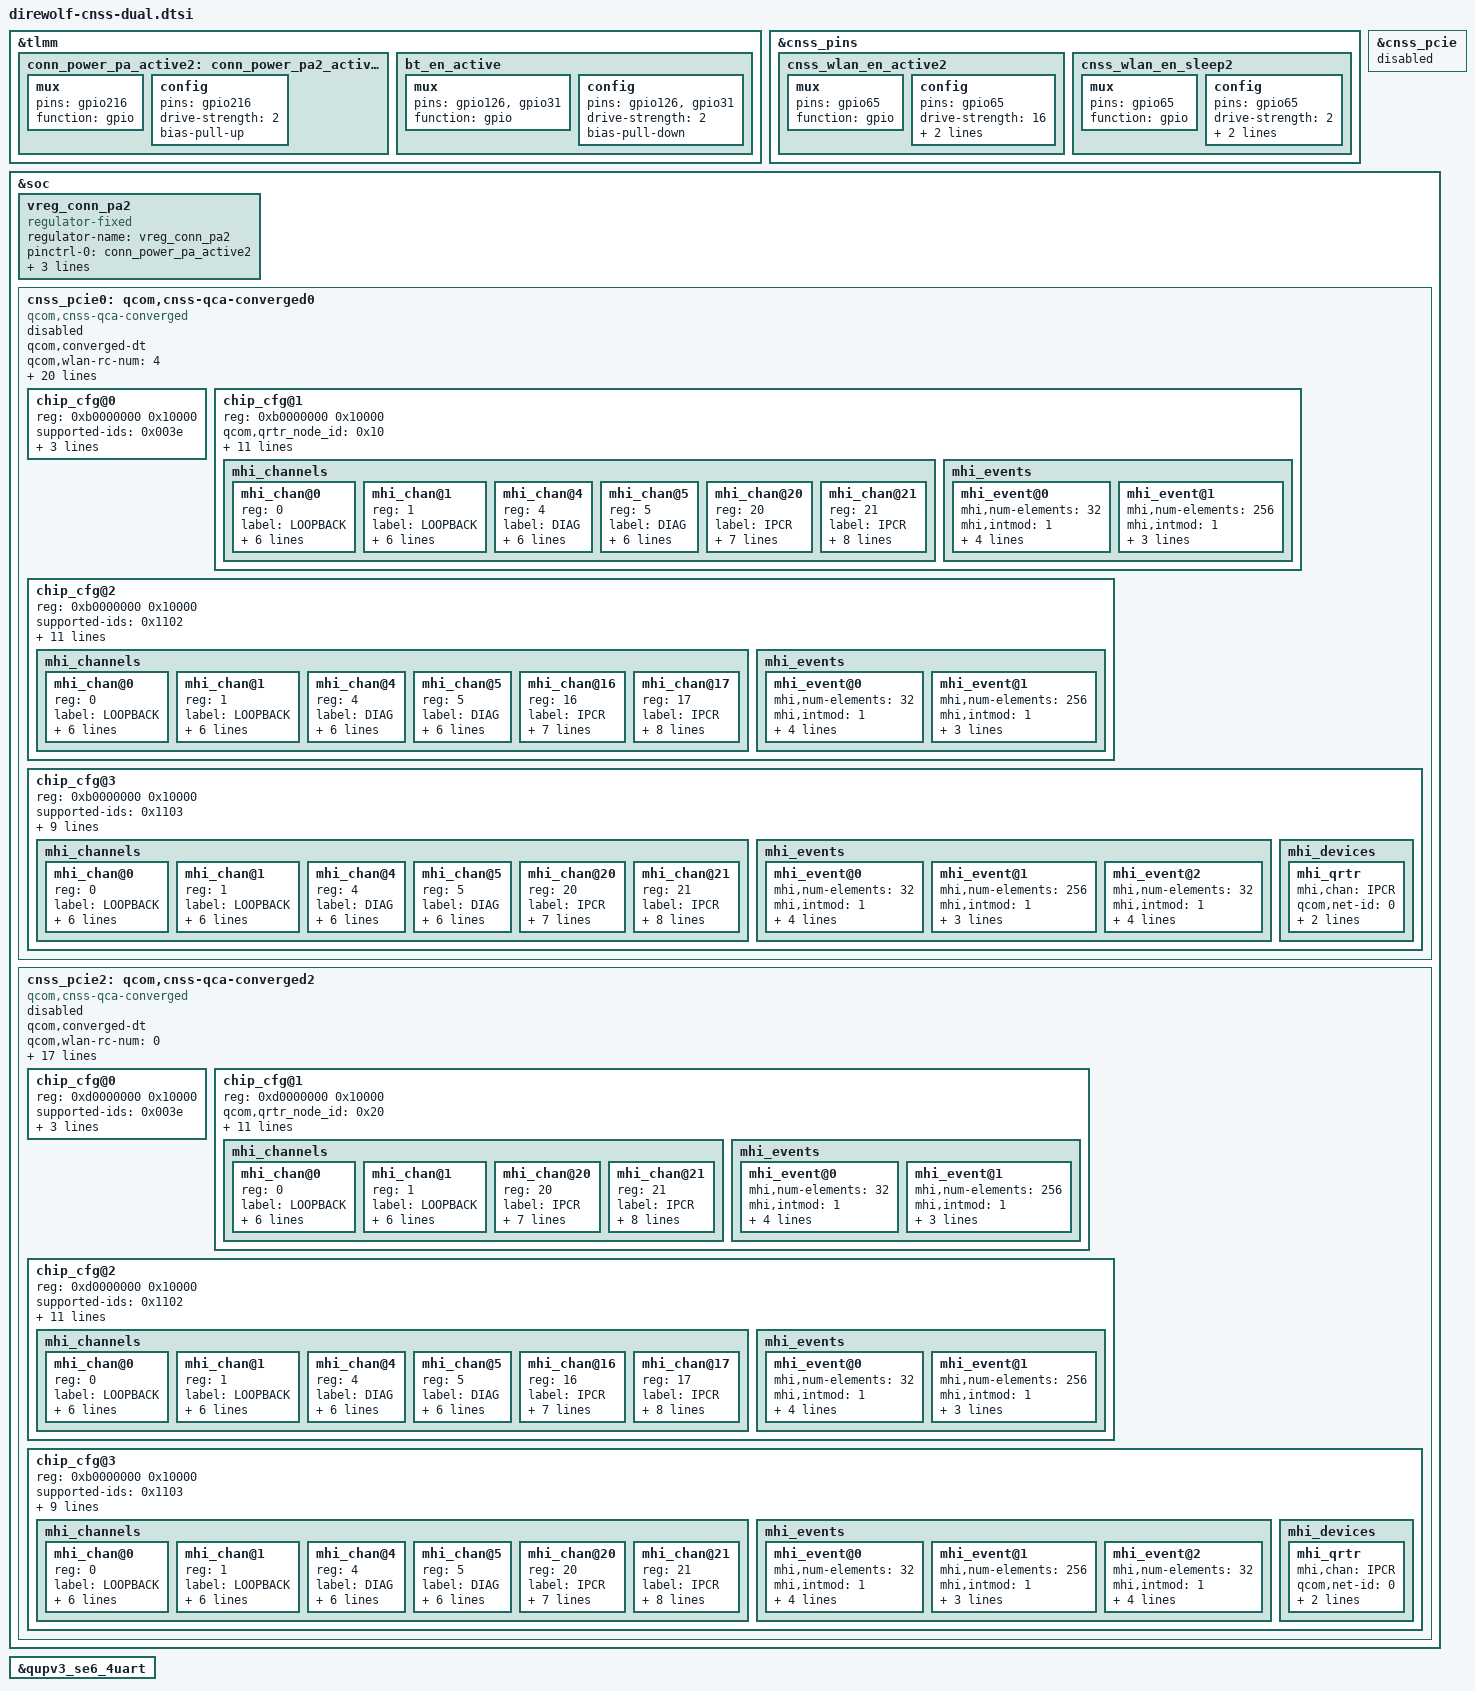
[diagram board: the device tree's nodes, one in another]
&tlmm {
	conn_power_pa_active2: conn_power_pa2_active2 {
		mux {
			pins = "gpio216";
			function = "gpio";
		};

		config {
			pins = "gpio216";
			drive-strength = <2>;
			bias-pull-up;
		};
	};
};

&cnss_pins {
	cnss_wlan_en_active2: cnss_wlan_en_active2 {
		mux {
			pins = "gpio65";
			function = "gpio";
		};

		config {
			pins = "gpio65";
			drive-strength = <16>;
			output-high;
			bias-pull-up;
		};
	};

	cnss_wlan_en_sleep2: cnss_wlan_en_sleep2 {
		mux {
			pins = "gpio65";
			function = "gpio";
		};

		config {
			pins = "gpio65";
			drive-strength = <2>;
			output-low;
			bias-pull-down;
		};
	};
};

&cnss_pcie {
	status = "disabled";
};

&soc {
	/* PWR_CTR1_VDD_PA supply for wlan2 */
	vreg_conn_pa2: vreg_conn_pa2 {
		compatible = "regulator-fixed";
		regulator-name = "vreg_conn_pa2";
		pinctrl-names = "default";
		pinctrl-0 = <&conn_power_pa_active2>;
		startup-delay-us = <4000>;
		enable-active-high;
		gpio = <&tlmm 216 0>;
	};

	/* Support Dual Hastings case */
	cnss_pcie0: qcom,cnss-qca-converged0 {
		compatible = "qcom,cnss-qca-converged";

		qcom,converged-dt;
		qcom,wlan-rc-num = <4>;
		qcom,pld_bus_ops_name = "pld_pcie_cnss2";
		qcom,bus-type=<0>;
		qcom,notify-modem-status;

		#address-cells=<1>;
		#size-cells=<1>;
		ranges = <0xb0000000 0xb0000000 0x10000>;

		vdd-wlan-ctrl1-supply = <&vreg_conn_pa>;
		vdd-wlan-ctrl2-supply = <&vreg_conn_1p8>;
		vdd-wlan-supply = <&vreg_wlan>;
		vdd-wlan-vl-supply = <&pm8540_e0_s4>;
		vdd-wlan-vm-supply = <&pm8540_g0_l6>;
		vdd-wlan-vh-supply = <&pm8540_a0_l15>;

		wlan_vregs = "vdd-wlan-ctrl1", "vdd-wlan-ctrl2", "vdd-wlan-vl",
				"vdd-wlan-vm", "vdd-wlan-vh";
		qcom,vdd-wlan-ctrl1-config = <0 0 0 0 0>;
		qcom,vdd-wlan-ctrl2-config = <0 0 0 0 0>;
		/* no vote-off as sw_ctrl is not supported */
		qcom,vdd-wlan-vl-config = <1055000 1055000 0 0 0>;
		/* No vol setting for bypass LDOs */
		qcom,vdd-wlan-vm-config = <0 0 0 0 0>;
		qcom,vdd-wlan-vh-config = <0 0 0 0 0>;
		wlan-en-gpio = <&tlmm 125 0>;
		qcom,bt-en-gpio = <&tlmm 126 0>;
		pinctrl-names = "wlan_en_active", "wlan_en_sleep";
		pinctrl-0 = <&cnss_wlan_en_active>;
		pinctrl-1 = <&cnss_wlan_en_sleep>;

		status = "disabled";

		chip_cfg@0 {
			reg = <0xb0000000 0x10000>;
			reg-names = "smmu_iova_ipa";

			supported-ids = <0x003e>;
			wlan_vregs = "vdd-wlan";
			qcom,vdd-wlan-config = <0 0 0 10 1>;

			qcom,wlan-ramdump-dynamic = <0x200000>;
		};

		chip_cfg@1 {
			reg = <0xb0000000 0x10000>;
			reg-names = "smmu_iova_ipa";
			qcom,qrtr_node_id = <0x10>;
			supported-ids = <0x1101>;
			wlan_vregs = "vdd-wlan-vl", "vdd-wlan-vm",
				   "vdd-wlan-vh";
			qcom,vdd-wlan-vl-config = <1055000 1055000 0 0 0>;
			qcom,vdd-wlan-vm-config = <0 0 0 0 0>;
			qcom,vdd-wlan-vh-config = <0 0 0 0 0>;

			qcom,wlan-ramdump-dynamic = <0x400000>;
			mhi,max-channels = <30>;
			mhi,timeout = <10000>;
			mhi,buffer-len = <0x8000>;
			mhi,m2-no-db-access;

			mhi_channels {
				#address-cells = <1>;
				#size-cells = <0>;
				mhi_chan@0 {
					reg = <0>;
					label = "LOOPBACK";
					mhi,num-elements = <32>;
					mhi,event-ring = <1>;
					mhi,chan-dir = <1>;
					mhi,data-type = <0>;
					mhi,doorbell-mode = <2>;
					mhi,ee = <0x14>;
				};

				mhi_chan@1 {
					reg = <1>;
					label = "LOOPBACK";
					mhi,num-elements = <32>;
					mhi,event-ring = <1>;
					mhi,chan-dir = <2>;
					mhi,data-type = <0>;
					mhi,doorbell-mode = <2>;
					mhi,ee = <0x14>;
				};

				mhi_chan@4 {
					reg = <4>;
					label = "DIAG";
					mhi,num-elements = <32>;
					mhi,event-ring = <1>;
					mhi,chan-dir = <1>;
					mhi,data-type = <0>;
					mhi,doorbell-mode = <2>;
					mhi,ee = <0x14>;
				};

				mhi_chan@5 {
					reg = <5>;
					label = "DIAG";
					mhi,num-elements = <32>;
					mhi,event-ring = <1>;
					mhi,chan-dir = <2>;
					mhi,data-type = <0>;
					mhi,doorbell-mode = <2>;
					mhi,ee = <0x14>;
				};

				mhi_chan@20 {
					reg = <20>;
					label = "IPCR";
					mhi,num-elements = <32>;
					mhi,event-ring = <1>;
					mhi,chan-dir = <1>;
					mhi,data-type = <1>;
					mhi,doorbell-mode = <2>;
					mhi,ee = <0x14>;
					mhi,auto-start;
				};

				mhi_chan@21 {
					reg = <21>;
					label = "IPCR";
					mhi,num-elements = <32>;
					mhi,event-ring = <1>;
					mhi,chan-dir = <2>;
					mhi,data-type = <0>;
					mhi,doorbell-mode = <2>;
					mhi,ee = <0x14>;
					mhi,auto-queue;
					mhi,auto-start;
				};
			};

			mhi_events {
				mhi_event@0 {
					mhi,num-elements = <32>;
					mhi,intmod = <1>;
					mhi,msi = <1>;
					mhi,priority = <1>;
					mhi,brstmode = <2>;
					mhi,data-type = <1>;
				};

				mhi_event@1 {
					mhi,num-elements = <256>;
					mhi,intmod = <1>;
					mhi,msi = <2>;
					mhi,priority = <1>;
					mhi,brstmode = <2>;
				};
			};
		};

		chip_cfg@2 {
			reg = <0xb0000000 0x10000>;
			reg-names = "smmu_iova_ipa";

			supported-ids = <0x1102>;
			wlan_vregs = "vdd-wlan-vl", "vdd-wlan-vm",
				   "vdd-wlan-vh";
			qcom,vdd-wlan-vl-config = <1055000 1055000 0 0 0>;
			qcom,vdd-wlan-vm-config = <0 0 0 0 0>;
			qcom,vdd-wlan-vh-config = <0 0 0 0 0>;

			qcom,wlan-ramdump-dynamic = <0x300000>;
			mhi,max-channels = <30>;
			mhi,timeout = <10000>;
			mhi,ee = <0x3>, <0x4>;
			mhi,ee-names = "SBL", "RDDM";
			mhi,bhie-offset = <0x0324>;

			mhi_channels {
				#address-cells = <1>;
				#size-cells = <0>;
				mhi_chan@0 {
					reg = <0>;
					label = "LOOPBACK";
					mhi,num-elements = <32>;
					mhi,event-ring = <1>;
					mhi,chan-dir = <1>;
					mhi,data-type = <0>;
					mhi,doorbell-mode = <2>;
					mhi,ee = <0x14>;
				};

				mhi_chan@1 {
					reg = <1>;
					label = "LOOPBACK";
					mhi,num-elements = <32>;
					mhi,event-ring = <1>;
					mhi,chan-dir = <2>;
					mhi,data-type = <0>;
					mhi,doorbell-mode = <2>;
					mhi,ee = <0x14>;
				};

				mhi_chan@4 {
					reg = <4>;
					label = "DIAG";
					mhi,num-elements = <32>;
					mhi,event-ring = <1>;
					mhi,chan-dir = <1>;
					mhi,data-type = <0>;
					mhi,doorbell-mode = <2>;
					mhi,ee = <0x14>;
				};

				mhi_chan@5 {
					reg = <5>;
					label = "DIAG";
					mhi,num-elements = <32>;
					mhi,event-ring = <1>;
					mhi,chan-dir = <2>;
					mhi,data-type = <0>;
					mhi,doorbell-mode = <2>;
					mhi,ee = <0x14>;
				};

				mhi_chan@16 {
					reg = <16>;
					label = "IPCR";
					mhi,num-elements = <32>;
					mhi,event-ring = <1>;
					mhi,chan-dir = <1>;
					mhi,data-type = <1>;
					mhi,doorbell-mode = <2>;
					mhi,ee = <0x14>;
					mhi,auto-start;
				};

				mhi_chan@17 {
					reg = <17>;
					label = "IPCR";
					mhi,num-elements = <32>;
					mhi,event-ring = <1>;
					mhi,chan-dir = <2>;
					mhi,data-type = <0>;
					mhi,doorbell-mode = <2>;
					mhi,ee = <0x14>;
					mhi,auto-queue;
					mhi,auto-start;
				};
			};

			mhi_events {
				mhi_event@0 {
					mhi,num-elements = <32>;
					mhi,intmod = <1>;
					mhi,msi = <1>;
					mhi,priority = <1>;
					mhi,brstmode = <2>;
					mhi,data-type = <1>;
				};

				mhi_event@1 {
					mhi,num-elements = <256>;
					mhi,intmod = <1>;
					mhi,msi = <2>;
					mhi,priority = <1>;
					mhi,brstmode = <2>;
				};
			};
		};

		chip_cfg@3 {
			reg = <0xb0000000 0x10000>;
			reg-names = "smmu_iova_ipa";

			supported-ids = <0x1103>;
			wlan_vregs = "vdd-wlan-vl", "vdd-wlan-vm",
				     "vdd-wlan-vh";
			qcom,vdd-wlan-vl-config = <1055000 1055000 0 0 0>;
			qcom,vdd-wlan-vm-config = <0 0 0 0 0>;
			qcom,vdd-wlan-vh-config = <0 0 0 0 0>;

			qcom,wlan-ramdump-dynamic = <0x420000>;
			mhi,max-channels = <30>;
			mhi,timeout = <10000>;
			mhi,m2-no-db-access;

			mhi_channels {
				#address-cells = <1>;
				#size-cells = <0>;
				mhi_chan@0 {
					reg = <0>;
					label = "LOOPBACK";
					mhi,num-elements = <32>;
					mhi,event-ring = <1>;
					mhi,chan-dir = <1>;
					mhi,data-type = <0>;
					mhi,doorbell-mode = <2>;
					mhi,ee = <0x14>;
				};

				mhi_chan@1 {
					reg = <1>;
					label = "LOOPBACK";
					mhi,num-elements = <32>;
					mhi,event-ring = <1>;
					mhi,chan-dir = <2>;
					mhi,data-type = <0>;
					mhi,doorbell-mode = <2>;
					mhi,ee = <0x14>;
				};

				mhi_chan@4 {
					reg = <4>;
					label = "DIAG";
					mhi,num-elements = <32>;
					mhi,event-ring = <1>;
					mhi,chan-dir = <1>;
					mhi,data-type = <0>;
					mhi,doorbell-mode = <2>;
					mhi,ee = <0x14>;
				};

				mhi_chan@5 {
					reg = <5>;
					label = "DIAG";
					mhi,num-elements = <32>;
					mhi,event-ring = <1>;
					mhi,chan-dir = <2>;
					mhi,data-type = <0>;
					mhi,doorbell-mode = <2>;
					mhi,ee = <0x14>;
				};

				mhi_chan@20 {
					reg = <20>;
					label = "IPCR";
					mhi,num-elements = <32>;
					mhi,event-ring = <1>;
					mhi,chan-dir = <1>;
					mhi,data-type = <1>;
					mhi,doorbell-mode = <2>;
					mhi,ee = <0x14>;
					mhi,auto-start;
				};

				mhi_chan@21 {
					reg = <21>;
					label = "IPCR";
					mhi,num-elements = <32>;
					mhi,event-ring = <1>;
					mhi,chan-dir = <2>;
					mhi,data-type = <0>;
					mhi,doorbell-mode = <2>;
					mhi,ee = <0x14>;
					mhi,auto-queue;
					mhi,auto-start;
				};
			};

			mhi_events {
				mhi_event@0 {
					mhi,num-elements = <32>;
					mhi,intmod = <1>;
					mhi,msi = <1>;
					mhi,priority = <1>;
					mhi,brstmode = <2>;
					mhi,data-type = <1>;
				};

				mhi_event@1 {
					mhi,num-elements = <256>;
					mhi,intmod = <1>;
					mhi,msi = <2>;
					mhi,priority = <1>;
					mhi,brstmode = <2>;
				};

				mhi_event@2 {
					mhi,num-elements = <32>;
					mhi,intmod = <1>;
					mhi,msi = <0>;
					mhi,priority = <2>;
					mhi,brstmode = <2>;
					mhi,data-type = <3>;
				};

			};

			mhi_devices {
				mhi_qrtr {
					mhi,chan = "IPCR";
					qcom,net-id = <0>;
					qcom,low-latency;
					mhi,early-notify;
				};
			};
		};
	};

	cnss_pcie2: qcom,cnss-qca-converged2 {
		compatible = "qcom,cnss-qca-converged";

		qcom,converged-dt;
		qcom,wlan-rc-num = <0>;
		qcom,pld_bus_ops_name = "pld_pcie_cnss0";
		qcom,bus-type=<0>;
		qcom,notify-modem-status;

		#address-cells=<1>;
		#size-cells=<1>;
		ranges = <0xd0000000 0xd0000000 0x10000>;

		vdd-wlan-ctrl1-supply = <&vreg_conn_pa2>;
		/*vdd-wlan-ctrl2-supply = <&vreg_conn_1p8>;*/
		vdd-wlan-supply = <&vreg_wlan>;
		vdd-wlan-vl-supply = <&pm8540_e0_s4>;
		vdd-wlan-vm-supply = <&pm8540_g0_l6>;
		vdd-wlan-vh-supply = <&pm8540_a0_l15>;

		wlan_vregs = "vdd-wlan-ctrl1", "vdd-wlan-vl",
				"vdd-wlan-vm", "vdd-wlan-vh";
		qcom,vdd-wlan-ctrl1-config = <0 0 0 0 0>;
		/*qcom,vdd-wlan-ctrl2-config = <0 0 0 0 0>;*/
		/* no vote-off as sw_ctrl is not supported */
		qcom,vdd-wlan-vl-config = <1055000 1055000 0 0 0>;
		/* No vol setting for bypass LDOs */
		qcom,vdd-wlan-vm-config = <0 0 0 0 0>;
		qcom,vdd-wlan-vh-config = <0 0 0 0 0>;
		wlan-en-gpio = <&tlmm 65 0>;
		pinctrl-names = "wlan_en_active", "wlan_en_sleep";
		pinctrl-0 = <&cnss_wlan_en_active2>;
		pinctrl-1 = <&cnss_wlan_en_sleep2>;

		status = "disabled";

		chip_cfg@0 {
			reg = <0xd0000000 0x10000>;
			reg-names = "smmu_iova_ipa";

			supported-ids = <0x003e>;
			wlan_vregs = "vdd-wlan";
			qcom,vdd-wlan-config = <0 0 0 10 1>;

			qcom,wlan-ramdump-dynamic = <0x200000>;
		};

		chip_cfg@1 {
			reg = <0xd0000000 0x10000>;
			reg-names = "smmu_iova_ipa";
			qcom,qrtr_node_id = <0x20>;
			supported-ids = <0x1101>;
			wlan_vregs = "vdd-wlan-vl", "vdd-wlan-vm",
				   "vdd-wlan-vh";
			qcom,vdd-wlan-vl-config = <1055000 1055000 0 0 0>;
			qcom,vdd-wlan-vm-config = <0 0 0 0 0>;
			qcom,vdd-wlan-vh-config = <0 0 0 0 0>;

			qcom,wlan-ramdump-dynamic = <0x400000>;
			mhi,max-channels = <30>;
			mhi,timeout = <10000>;
			mhi,buffer-len = <0x8000>;
			mhi,m2-no-db-access;

			mhi_channels {
				#address-cells = <1>;
				#size-cells = <0>;
				mhi_chan@0 {
					reg = <0>;
					label = "LOOPBACK";
					mhi,num-elements = <32>;
					mhi,event-ring = <1>;
					mhi,chan-dir = <1>;
					mhi,data-type = <0>;
					mhi,doorbell-mode = <2>;
					mhi,ee = <0x14>;
				};

				mhi_chan@1 {
					reg = <1>;
					label = "LOOPBACK";
					mhi,num-elements = <32>;
					mhi,event-ring = <1>;
					mhi,chan-dir = <2>;
					mhi,data-type = <0>;
					mhi,doorbell-mode = <2>;
					mhi,ee = <0x14>;
				};

				mhi_chan@20 {
					reg = <20>;
					label = "IPCR";
					mhi,num-elements = <32>;
					mhi,event-ring = <1>;
					mhi,chan-dir = <1>;
					mhi,data-type = <1>;
					mhi,doorbell-mode = <2>;
					mhi,ee = <0x14>;
					mhi,auto-start;
				};

				mhi_chan@21 {
					reg = <21>;
					label = "IPCR";
					mhi,num-elements = <32>;
					mhi,event-ring = <1>;
					mhi,chan-dir = <2>;
					mhi,data-type = <0>;
					mhi,doorbell-mode = <2>;
					mhi,ee = <0x14>;
					mhi,auto-queue;
					mhi,auto-start;
				};
			};

			mhi_events {
				mhi_event@0 {
					mhi,num-elements = <32>;
					mhi,intmod = <1>;
					mhi,msi = <1>;
					mhi,priority = <1>;
					mhi,brstmode = <2>;
					mhi,data-type = <1>;
				};

				mhi_event@1 {
					mhi,num-elements = <256>;
					mhi,intmod = <1>;
					mhi,msi = <2>;
					mhi,priority = <1>;
					mhi,brstmode = <2>;
				};
			};
		};

		chip_cfg@2 {
			reg = <0xd0000000 0x10000>;
			reg-names = "smmu_iova_ipa";

			supported-ids = <0x1102>;
			wlan_vregs = "vdd-wlan-vl", "vdd-wlan-vm",
				   "vdd-wlan-vh";
			qcom,vdd-wlan-vl-config = <1055000 1055000 0 0 0>;
			qcom,vdd-wlan-vm-config = <0 0 0 0 0>;
			qcom,vdd-wlan-vh-config = <0 0 0 0 0>;

			qcom,wlan-ramdump-dynamic = <0x300000>;
			mhi,max-channels = <30>;
			mhi,timeout = <10000>;
			mhi,ee = <0x3>, <0x4>;
			mhi,ee-names = "SBL", "RDDM";
			mhi,bhie-offset = <0x0324>;

			mhi_channels {
				#address-cells = <1>;
				#size-cells = <0>;
				mhi_chan@0 {
					reg = <0>;
					label = "LOOPBACK";
					mhi,num-elements = <32>;
					mhi,event-ring = <1>;
					mhi,chan-dir = <1>;
					mhi,data-type = <0>;
					mhi,doorbell-mode = <2>;
					mhi,ee = <0x14>;
				};

				mhi_chan@1 {
					reg = <1>;
					label = "LOOPBACK";
					mhi,num-elements = <32>;
					mhi,event-ring = <1>;
					mhi,chan-dir = <2>;
					mhi,data-type = <0>;
					mhi,doorbell-mode = <2>;
					mhi,ee = <0x14>;
				};

				mhi_chan@4 {
					reg = <4>;
					label = "DIAG";
					mhi,num-elements = <32>;
					mhi,event-ring = <1>;
					mhi,chan-dir = <1>;
					mhi,data-type = <0>;
					mhi,doorbell-mode = <2>;
					mhi,ee = <0x14>;
				};

				mhi_chan@5 {
					reg = <5>;
					label = "DIAG";
					mhi,num-elements = <32>;
					mhi,event-ring = <1>;
					mhi,chan-dir = <2>;
					mhi,data-type = <0>;
					mhi,doorbell-mode = <2>;
					mhi,ee = <0x14>;
				};

				mhi_chan@16 {
					reg = <16>;
					label = "IPCR";
					mhi,num-elements = <32>;
					mhi,event-ring = <1>;
					mhi,chan-dir = <1>;
					mhi,data-type = <1>;
					mhi,doorbell-mode = <2>;
					mhi,ee = <0x14>;
					mhi,auto-start;
				};

				mhi_chan@17 {
					reg = <17>;
					label = "IPCR";
					mhi,num-elements = <32>;
					mhi,event-ring = <1>;
					mhi,chan-dir = <2>;
					mhi,data-type = <0>;
					mhi,doorbell-mode = <2>;
					mhi,ee = <0x14>;
					mhi,auto-queue;
					mhi,auto-start;
				};
			};

			mhi_events {
				mhi_event@0 {
					mhi,num-elements = <32>;
					mhi,intmod = <1>;
					mhi,msi = <1>;
					mhi,priority = <1>;
					mhi,brstmode = <2>;
					mhi,data-type = <1>;
				};

				mhi_event@1 {
					mhi,num-elements = <256>;
					mhi,intmod = <1>;
					mhi,msi = <2>;
					mhi,priority = <1>;
					mhi,brstmode = <2>;
				};
			};
		};

		chip_cfg@3 {
			reg = <0xb0000000 0x10000>;
			reg-names = "smmu_iova_ipa";

			supported-ids = <0x1103>;
			wlan_vregs = "vdd-wlan-vl", "vdd-wlan-vm",
				     "vdd-wlan-vh";
			qcom,vdd-wlan-vl-config = <1055000 1055000 0 0 0>;
			qcom,vdd-wlan-vm-config = <0 0 0 0 0>;
			qcom,vdd-wlan-vh-config = <0 0 0 0 0>;

			qcom,wlan-ramdump-dynamic = <0x420000>;
			mhi,max-channels = <30>;
			mhi,timeout = <10000>;
			mhi,m2-no-db-access;

			mhi_channels {
				#address-cells = <1>;
				#size-cells = <0>;
				mhi_chan@0 {
					reg = <0>;
					label = "LOOPBACK";
					mhi,num-elements = <32>;
					mhi,event-ring = <1>;
					mhi,chan-dir = <1>;
					mhi,data-type = <0>;
					mhi,doorbell-mode = <2>;
					mhi,ee = <0x14>;
				};

				mhi_chan@1 {
					reg = <1>;
					label = "LOOPBACK";
					mhi,num-elements = <32>;
					mhi,event-ring = <1>;
					mhi,chan-dir = <2>;
					mhi,data-type = <0>;
					mhi,doorbell-mode = <2>;
					mhi,ee = <0x14>;
				};

				mhi_chan@4 {
					reg = <4>;
					label = "DIAG";
					mhi,num-elements = <32>;
					mhi,event-ring = <1>;
					mhi,chan-dir = <1>;
					mhi,data-type = <0>;
					mhi,doorbell-mode = <2>;
					mhi,ee = <0x14>;
				};

				mhi_chan@5 {
					reg = <5>;
					label = "DIAG";
					mhi,num-elements = <32>;
					mhi,event-ring = <1>;
					mhi,chan-dir = <2>;
					mhi,data-type = <0>;
					mhi,doorbell-mode = <2>;
					mhi,ee = <0x14>;
				};

				mhi_chan@20 {
					reg = <20>;
					label = "IPCR";
					mhi,num-elements = <32>;
					mhi,event-ring = <1>;
					mhi,chan-dir = <1>;
					mhi,data-type = <1>;
					mhi,doorbell-mode = <2>;
					mhi,ee = <0x14>;
					mhi,auto-start;
				};

				mhi_chan@21 {
					reg = <21>;
					label = "IPCR";
					mhi,num-elements = <32>;
					mhi,event-ring = <1>;
					mhi,chan-dir = <2>;
					mhi,data-type = <0>;
					mhi,doorbell-mode = <2>;
					mhi,ee = <0x14>;
					mhi,auto-queue;
					mhi,auto-start;
				};
			};

			mhi_events {
				mhi_event@0 {
					mhi,num-elements = <32>;
					mhi,intmod = <1>;
					mhi,msi = <1>;
					mhi,priority = <1>;
					mhi,brstmode = <2>;
					mhi,data-type = <1>;
				};

				mhi_event@1 {
					mhi,num-elements = <256>;
					mhi,intmod = <1>;
					mhi,msi = <2>;
					mhi,priority = <1>;
					mhi,brstmode = <2>;
				};

				mhi_event@2 {
					mhi,num-elements = <32>;
					mhi,intmod = <1>;
					mhi,msi = <0>;
					mhi,priority = <2>;
					mhi,brstmode = <2>;
					mhi,data-type = <3>;
				};

			};

			mhi_devices {
				mhi_qrtr {
					mhi,chan = "IPCR";
					qcom,net-id = <0>;
					qcom,low-latency;
					mhi,early-notify;
				};
			};
		};
	};
};

&tlmm {
	bt_en_active: bt_en_active {
		mux {
			pins = "gpio126", "gpio31";
			function = "gpio";
		};

		config {
			pins = "gpio126", "gpio31";
			drive-strength = <2>;
			bias-pull-down;
		};
	};
};

&qupv3_se6_4uart {
	status = "ok";
};
